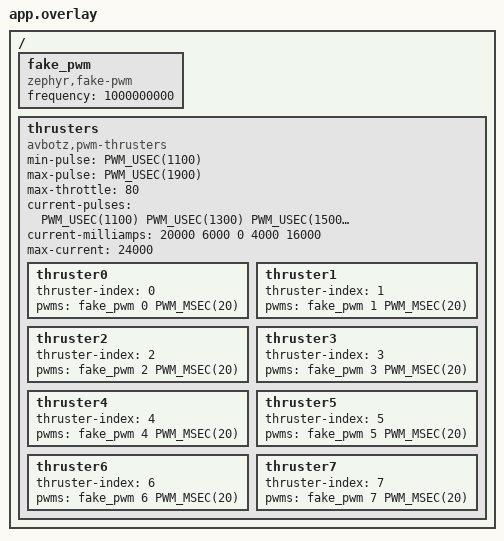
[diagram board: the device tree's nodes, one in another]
#include <zephyr/dt-bindings/pwm/pwm.h>

/ {
	fake_pwm: fake_pwm {
		compatible = "zephyr,fake-pwm";
		#pwm-cells = <2>;
		/* One cycle is one nanosecond */
		frequency = <1000000000>;
	};

	/* Not the T200's values: these are chosen so the limits can be worked out by hand. */
	thrusters {
		compatible = "avbotz,pwm-thrusters";

		min-pulse = <PWM_USEC(1100)>;
		max-pulse = <PWM_USEC(1900)>;

		max-throttle = <80>;

		current-pulses = <PWM_USEC(1100) PWM_USEC(1300) PWM_USEC(1500) PWM_USEC(1700)
				  PWM_USEC(1900)>;
		current-milliamps = <20000 6000 0 4000 16000>;

		max-current = <24000>;

		thruster0 {
			thruster-index = <0>;
			pwms = <&fake_pwm 0 PWM_MSEC(20)>;
		};

		thruster1 {
			thruster-index = <1>;
			pwms = <&fake_pwm 1 PWM_MSEC(20)>;
		};

		thruster2 {
			thruster-index = <2>;
			pwms = <&fake_pwm 2 PWM_MSEC(20)>;
		};

		thruster3 {
			thruster-index = <3>;
			pwms = <&fake_pwm 3 PWM_MSEC(20)>;
		};

		thruster4 {
			thruster-index = <4>;
			pwms = <&fake_pwm 4 PWM_MSEC(20)>;
		};

		thruster5 {
			thruster-index = <5>;
			pwms = <&fake_pwm 5 PWM_MSEC(20)>;
		};

		thruster6 {
			thruster-index = <6>;
			pwms = <&fake_pwm 6 PWM_MSEC(20)>;
		};

		thruster7 {
			thruster-index = <7>;
			pwms = <&fake_pwm 7 PWM_MSEC(20)>;
		};
	};
};
